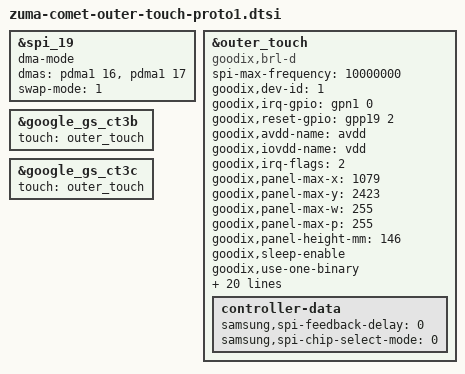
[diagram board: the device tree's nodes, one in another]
// SPDX-License-Identifier: GPL-2.0-only
/*
 * Google Comet touch device tree source
 *
 * Copyright 2023 Google LLC.
 *
 */

#include "zuma-comet-outer-common-touch.dtsi"

&spi_19 {
	dma-mode;
	dmas = <&pdma1 16 &pdma1 17>;
	swap-mode = <1>;
};


&outer_touch {
	status = "okay";
	compatible = "goodix,brl-d";

	spi-max-frequency = <10000000>;

	goodix,dev-id = <1>;
	goodix,irq-gpio = <&gpn1 0 0>;
	goodix,reset-gpio = <&gpp19 2 0>;
	goodix,avdd-name = "avdd";
	goodix,iovdd-name = "vdd";
	goodix,irq-flags = <2>; /* 1:trigger rising, 2:trigger falling;*/
	goodix,panel-max-x = <1079>;
	goodix,panel-max-y = <2423>;
	goodix,panel-max-w = <255>;
	goodix,panel-max-p = <255>;
	goodix,panel-height-mm = <146>;
	goodix,sleep-enable;
	goodix,use-one-binary;

	goog,panel_map = <&google_gs_ct3b 0>,
			<&google_gs_ct3c 1>;

	goog,firmware_names = "goodix_firmware_outer_dev1.bin",
			"goodix_firmware_outer.bin";
	goodix,firmware-name = "goodix_firmware_outer.bin";

	goog,config_names = "goodix_cfg_group_outer_dev1.bin",
			"goodix_cfg_group_outer.bin";
	goodix,config-name = "goodix_cfg_group_outer.bin";

	goog,test_limits_names = "goodix_test_limits_outer_dev1.csv",
				"goodix_test_limits_outer.csv";
	goodix,test-limits-name = "goodix_test_limits_outer.csv";

	goog,dev-id = <1>;
	goog,offload-device-name = "outer";
	goog,display-resolution = /bits/ 16 <1080 2424>;
	goog,channel-num = /bits/ 16 <16 36>;

	controller-data {
		samsung,spi-feedback-delay = <0>;
		samsung,spi-chip-select-mode = <0>;
	};

};

&google_gs_ct3b {
	touch = <&outer_touch>;
};

&google_gs_ct3c {
	touch = <&outer_touch>;
};
